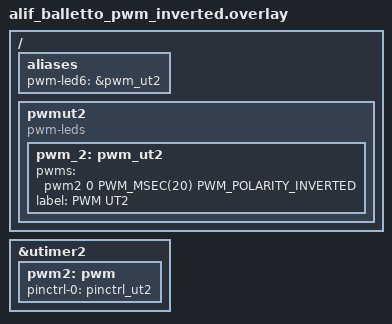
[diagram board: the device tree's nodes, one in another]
/* Copyright Alif Semiconductor - All Rights Reserved.
 * Use, distribution and modification of this code is permitted under the
 * terms stated in the Alif Semiconductor Software License Agreement
 *
 * You should have received a copy of the Alif Semiconductor Software
 * License Agreement with this file. If not, please write to:
 * contact@alifsemi.com, or visit: https://alifsemi.com/license
 */
/ {
		aliases {
				pwm-led6 = &pwm_ut2;
		};
		pwmut2 {
				compatible = "pwm-leds";
				pwm_2: pwm_ut2 {
				pwms = <&pwm2 0 PWM_MSEC(20) PWM_POLARITY_INVERTED>;
				label = "PWM UT2";
			};
		};
};

&utimer2 {
		status = "okay";

		pwm2: pwm {
				pinctrl-0 = < &pinctrl_ut2 >;
				pinctrl-names = "default";
				status = "okay";
		};
};
